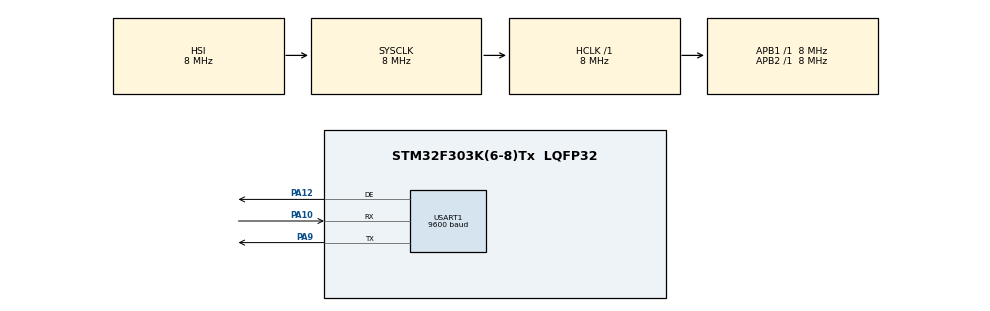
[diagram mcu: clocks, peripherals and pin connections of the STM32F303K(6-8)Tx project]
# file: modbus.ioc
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Mcu.Family=STM32F3
Mcu.Name=STM32F303K(6-8)Tx
Mcu.Package=LQFP32
NVIC.PriorityGroup=NVIC_PRIORITYGROUP_4
NVIC.USART1_IRQn=true\:0\:0\:false\:false\:true\:true\:true\:true
PA10.Mode=Asynchronous
PA10.Signal=USART1_RX
PA12.Mode=Hardware Flow Control (RS485)
PA12.Signal=USART1_DE
PA9.Mode=Asynchronous
PA9.Signal=USART1_TX
ProjectManager.HeapSize=0x200
ProjectManager.StackSize=0x400
ProjectManager.TargetToolchain=STM32CubeIDE
RCC.AHBFreq_Value=8000000
RCC.APB1Freq_Value=8000000
RCC.APB2Freq_Value=8000000
RCC.CortexFreq_Value=8000000
RCC.HSE_VALUE=8000000
RCC.HSI_VALUE=8000000
RCC.SYSCLKFreq_VALUE=8000000
USART1.BaudRate=9600
USART1.Parity=PARITY_EVEN
USART1.VirtualMode-Asynchronous=VM_ASYNC
USART1.VirtualMode-Hardware\ Flow\ Control\ (RS485)=VM_ASYNC
board=custom

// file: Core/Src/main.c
/* USER CODE BEGIN Header */
/**
 ******************************************************************************
 * @file           : main.c
 * @brief          : Main program body
 ******************************************************************************
 * @attention
 *
 * Copyright (c) 2025 STMicroelectronics.
 * All rights reserved.
 *
 * This software is licensed under terms that can be found in the LICENSE file
 * in the root directory of this software component.
 * If no LICENSE file comes with this software, it is provided AS-IS.
 *
 ******************************************************************************
 */
/* USER CODE END Header */
#include "main.h"
#include "modbus.h"
#include "modbus_conf.h"
#include "mydevice.h"

/* USER CODE BEGIN Includes */
#include "modbus.h"
#include "modbus_conf.h"
#include "mydevice.h"
#include <stdio.h>
/* USER CODE END Includes */

UART_HandleTypeDef huart1;

/* USER CODE BEGIN PV */
mbus_t mb_ctx;
uint8_t rx_byte; // Declare globally for UART
/* USER CODE END PV */

void SystemClock_Config(void);
static void MX_GPIO_Init(void);
static void MX_USART1_UART_Init(void);
/* USER CODE BEGIN PFP */
extern void initialise_monitor_handles(void);
/* USER CODE END PFP */

int main(void)
{

  /* USER CODE BEGIN 1 */
  initialise_monitor_handles(); // Initialize semihosting for printf
  /* USER CODE END 1 */

  /* MCU Configuration--------------------------------------------------------*/

  /* Reset of all peripherals, Initializes the Flash interface and the Systick. */
  HAL_Init();

  /* Configure the system clock */
  SystemClock_Config();

  /* Initialize all configured peripherals */
  MX_GPIO_Init();
  MX_USART1_UART_Init();
  /* USER CODE BEGIN 2 */
  mb_ctx = mbus_somedevice_open(NULL);
  mbus_connect(mb_ctx, mbus_somedevice_read_3xxxx, MBUS_FUNC_READ_REGS); // Register read handler
  printf("Handler registered for function %d\n", MBUS_FUNC_READ_REGS);
  mbus_connect(mb_ctx, mbus_somedevice_write_4xxxx, MBUS_FUNC_WRITE_REGS); // Register write handler
  printf("Handlers Registered\n");
  HAL_UART_Receive_IT(&huart1, &rx_byte, 1); // Start UART reception
  /* USER CODE END 2 */

  /* Infinite loop */
  while (1)
  {

    /* USER CODE BEGIN 3 */
    // Main loop - polling is handled in UART interrupt
    /* USER CODE END 3 */
  }
  /* USER CODE END 3 */
}

void SystemClock_Config(void)
{
  RCC_OscInitTypeDef RCC_OscInitStruct = {0};
  RCC_ClkInitTypeDef RCC_ClkInitStruct = {0};
  RCC_PeriphCLKInitTypeDef PeriphClkInit = {0};

  /** Initializes the RCC Oscillators according to the specified parameters
   * in the RCC_OscInitTypeDef structure.
   */
  RCC_OscInitStruct.OscillatorType = RCC_OSCILLATORTYPE_HSI;
  RCC_OscInitStruct.HSIState = RCC_HSI_ON;
  RCC_OscInitStruct.HSICalibrationValue = RCC_HSICALIBRATION_DEFAULT;
  RCC_OscInitStruct.PLL.PLLState = RCC_PLL_NONE;
  if (HAL_RCC_OscConfig(&RCC_OscInitStruct) != HAL_OK)
  {
    Error_Handler();
  }

  /** Initializes the CPU, AHB and APB buses clocks
   */
  RCC_ClkInitStruct.ClockType = RCC_CLOCKTYPE_HCLK | RCC_CLOCKTYPE_SYSCLK | RCC_CLOCKTYPE_PCLK1 | RCC_CLOCKTYPE_PCLK2;
  RCC_ClkInitStruct.SYSCLKSource = RCC_SYSCLKSOURCE_HSI;
  RCC_ClkInitStruct.AHBCLKDivider = RCC_SYSCLK_DIV1;
  RCC_ClkInitStruct.APB1CLKDivider = RCC_HCLK_DIV1;
  RCC_ClkInitStruct.APB2CLKDivider = RCC_HCLK_DIV1;

  if (HAL_RCC_ClockConfig(&RCC_ClkInitStruct, FLASH_LATENCY_0) != HAL_OK)
  {
    Error_Handler();
  }
  PeriphClkInit.PeriphClockSelection = RCC_PERIPHCLK_USART1;
  PeriphClkInit.Usart1ClockSelection = RCC_USART1CLKSOURCE_PCLK1;
  if (HAL_RCCEx_PeriphCLKConfig(&PeriphClkInit) != HAL_OK)
  {
    Error_Handler();
  }
}

static void MX_USART1_UART_Init(void)
{

  huart1.Instance = USART1;
  huart1.Init.BaudRate = 9600;
  huart1.Init.WordLength = UART_WORDLENGTH_8B;
  huart1.Init.StopBits = UART_STOPBITS_1;
  huart1.Init.Parity = UART_PARITY_EVEN;
  huart1.Init.Mode = UART_MODE_TX_RX;
  huart1.Init.HwFlowCtl = UART_HWCONTROL_NONE;
  huart1.Init.OverSampling = UART_OVERSAMPLING_8;
  huart1.Init.OneBitSampling = UART_ONE_BIT_SAMPLE_DISABLE;
  huart1.AdvancedInit.AdvFeatureInit = UART_ADVFEATURE_NO_INIT;
  if (HAL_RS485Ex_Init(&huart1, UART_DE_POLARITY_HIGH, 0, 0) != HAL_OK)
  {
    Error_Handler();
  }
  /* USER CODE BEGIN USART1_Init 2 */
  HAL_UART_Receive_IT(&huart1, &rx_byte, 1); // Start receiving
  /* USER CODE END USART1_Init 2 */
}

static void MX_GPIO_Init(void)
{

  /* GPIO Ports Clock Enable */
  __HAL_RCC_GPIOA_CLK_ENABLE();

}

/* USER CODE BEGIN 4 */
void HAL_UART_RxCpltCallback(UART_HandleTypeDef *huart)
{
  if (huart == &huart1)
  {
    printf("RX Byte: 0x%02X\n", rx_byte); // Print directly
    mbus_poll(mb_ctx, rx_byte);
    HAL_UART_Receive_IT(&huart1, &rx_byte, 1);
  }
  if (HAL_UART_GetError(&huart1) != HAL_UART_ERROR_NONE)
  {
    printf("UART Error\n");
    HAL_UART_Abort(&huart1);
    HAL_UART_Receive_IT(&huart1, &rx_byte, 1);
  }
  if (HAL_UART_GetError(&huart1) & HAL_UART_ERROR_ORE)
  {
    printf("Overrun Error\n");
  }

  /* rx_byte = test_frame[test_idx++];
  if (test_idx >= 8) test_idx = 0; */
}
/* USER CODE END 4 */

void Error_Handler(void)
{
  __disable_irq();
  while (1)
  {
  }
}
